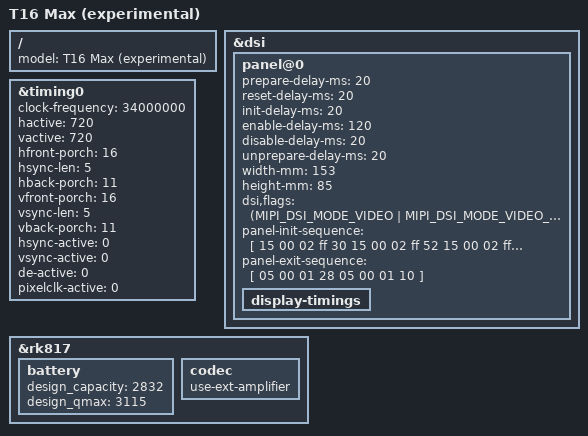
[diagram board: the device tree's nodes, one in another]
// SPDX-License-Identifier: (GPL-2.0+ OR MIT)
/*
 * EXPERIMENTAL - not tested on hardware by andr36oid. Keep a copy of the
 * files you replace so you can go back.
 *
 * T16 Max, first version (eMMC model): as the R39 Max (K36 wiring, 720x720
 * panel at 34 MHz) but the speaker runs through an external amplifier.
 * Values from the stock DTB dumped from the console.
 */

/dts-v1/;
#include "rk3326-r36s-clone-ee-k36.dtsi"
#include "rk3326-r36s-square.dtsi"

/ {
	model = "T16 Max (experimental)";
};

&dsi {
	panel@0 {
		prepare-delay-ms = <20>;
		reset-delay-ms = <20>;
		init-delay-ms = <20>;
		enable-delay-ms = <120>;
		disable-delay-ms = <20>;
		unprepare-delay-ms = <20>;
		width-mm = <153>;
		height-mm = <85>;
		dsi,flags = <(MIPI_DSI_MODE_VIDEO |
		      MIPI_DSI_MODE_VIDEO_BURST |
		      MIPI_DSI_MODE_EOT_PACKET |
		      MIPI_DSI_MODE_LPM)>;
		panel-init-sequence = [
			15 00 02 ff 30
			15 00 02 ff 52
			15 00 02 ff 01
			15 00 02 e3 01
			15 00 02 28 5f
			15 00 02 29 c2
			15 00 02 2a cf
			15 00 02 30 58
			15 00 02 37 bc
			15 00 02 38 c7
			15 00 02 39 01
			15 00 02 44 00
			15 00 02 49 3c
			15 00 02 59 fe
			15 00 02 5c 00
			15 00 02 80 20
			15 00 02 91 77
			15 00 02 92 77
			15 00 02 99 15
			15 00 02 9b 10
			15 00 02 a0 55
			15 00 02 a1 50
			15 00 02 a4 9c
			15 00 02 a7 02
			15 00 02 a8 01
			15 00 02 a9 21
			15 00 02 aa fc
			15 00 02 ab 28
			15 00 02 ac 06
			15 00 02 ad 06
			15 00 02 ae 06
			15 00 02 af 03
			15 00 02 b0 08
			15 00 02 b1 26
			15 00 02 b2 28
			15 00 02 b3 28
			15 00 02 b4 03
			15 00 02 b5 08
			15 00 02 b6 26
			15 00 02 b7 08
			15 00 02 b8 26
			15 00 02 c0 00
			15 00 02 c1 00
			15 00 02 c2 00
			15 00 02 c3 0f
			15 00 02 ff 30
			15 00 02 ff 52
			15 00 02 ff 02
			15 00 02 ff 30
			15 00 02 ff 52
			15 00 02 ff 02
			15 00 02 b0 05
			15 00 02 b1 15
			15 00 02 b2 16
			15 00 02 b3 3b
			15 00 02 b4 38
			15 00 02 b5 37
			15 00 02 b6 28
			15 00 02 b7 4a
			15 00 02 b8 0f
			15 00 02 b9 08
			15 00 02 ba 13
			15 00 02 bb 12
			15 00 02 bc 13
			15 00 02 bd 15
			15 00 02 be 1c
			15 00 02 bf 12
			15 00 02 c0 18
			15 00 02 c1 0a
			15 00 02 d0 05
			15 00 02 d1 0b
			15 00 02 d2 0c
			15 00 02 d3 31
			15 00 02 d4 2e
			15 00 02 d5 37
			15 00 02 d6 1e
			15 00 02 d7 40
			15 00 02 d8 0b
			15 00 02 d9 02
			15 00 02 da 0f
			15 00 02 db 0e
			15 00 02 dc 0f
			15 00 02 dd 11
			15 00 02 de 18
			15 00 02 df 0e
			15 00 02 e0 14
			15 00 02 e1 06
			15 00 02 ff 30
			15 00 02 ff 52
			15 00 02 ff 03
			15 00 02 07 00
			15 00 02 08 87
			15 00 02 09 86
			15 00 02 34 a1
			15 00 02 35 07
			15 00 02 36 07
			15 00 02 37 33
			15 00 02 40 85
			15 00 02 41 84
			15 00 02 42 83
			15 00 02 43 82
			15 00 02 44 22
			15 00 02 45 d0
			15 00 02 46 d1
			15 00 02 47 22
			15 00 02 48 d2
			15 00 02 49 d3
			15 00 02 50 81
			15 00 02 51 00
			15 00 02 52 01
			15 00 02 53 02
			15 00 02 54 22
			15 00 02 55 d4
			15 00 02 56 d5
			15 00 02 57 22
			15 00 02 58 d6
			15 00 02 59 d7
			15 00 02 80 0f
			15 00 02 82 0f
			15 00 02 84 0f
			15 00 02 86 0e
			15 00 02 88 07
			15 00 02 89 06
			15 00 02 8a 05
			15 00 02 8b 04
			15 00 02 8d 00
			15 00 02 8f 0f
			15 00 02 91 0f
			15 00 02 92 0f
			15 00 02 94 0e
			15 00 02 95 0e
			15 00 02 96 0f
			15 00 02 98 0f
			15 00 02 9a 0f
			15 00 02 9c 0e
			15 00 02 9e 07
			15 00 02 9f 06
			15 00 02 a0 05
			15 00 02 a1 04
			15 00 02 a3 00
			15 00 02 a5 0f
			15 00 02 a7 0f
			15 00 02 a8 0f
			15 00 02 aa 0e
			15 00 02 ab 0e
			15 00 02 e0 02
			15 00 02 e1 52
			15 00 02 ff 30
			15 00 02 ff 52
			15 00 02 ff 00
			15 00 02 36 02
			15 00 02 53 2c
			05 c8 01 11
			05 64 01 29
		];
		panel-exit-sequence = [
			05 00 01 28
			05 00 01 10
		];
		display-timings {
			/* one mode only: the R36S alternates below do not fit this panel */
			/delete-node/ timing1;
			/delete-node/ timing2;
		};
	};
};

&timing0 {
	clock-frequency = <34000000>;
	hactive = <720>;
	vactive = <720>;
	hfront-porch = <16>;
	hsync-len = <5>;
	hback-porch = <11>;
	vfront-porch = <16>;
	vsync-len = <5>;
	vback-porch = <11>;
	hsync-active = <0>;
	vsync-active = <0>;
	de-active = <0>;
	pixelclk-active = <0>;
};

&rk817 {
	battery {
		design_capacity = <2832>;
		design_qmax = <3115>;
	};
};

/* the speaker runs through an external amplifier (stock "use-ext-amplifier") */
&rk817 {
	codec {
		use-ext-amplifier;
	};
};
